AUTOSAR XML (schema 4-3-0)
package /Hackathon/Interfaces
  sender receiver interface WdgM_AliveInterface
    data AliveCounter: type=uint8
  client server interface WdgM_TriggerInterface
    operation Trigger: possible-error=E_NOT_OK
      arg SupervisionEntityId: direction=IN, type=uint16
    error E_NOT_OK: error-code=1
package /Hackathon/Components
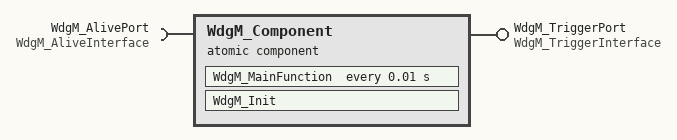
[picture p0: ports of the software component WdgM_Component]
  atomic sw component type WdgM_Component
    provide port WdgM_TriggerPort: provided-interface=WdgM_TriggerInterface
    require port WdgM_AlivePort: required-interface=WdgM_AliveInterface
    behavior WdgM_InternalBehavior
      runnable WdgM_MainFunction
      runnable WdgM_Init
      timing event WdgM_MainFunction_10ms: start-on-event=WdgM_MainFunction, period=0.01
      init event WdgM_Init_Event: start-on-event=WdgM_Init
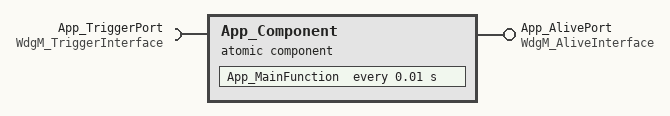
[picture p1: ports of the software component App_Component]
  atomic sw component type App_Component
    require port App_TriggerPort: required-interface=WdgM_TriggerInterface
    provide port App_AlivePort: provided-interface=WdgM_AliveInterface
    behavior App_InternalBehavior
      runnable App_MainFunction
      timing event App_MainFunction_10ms: start-on-event=App_MainFunction, period=0.01
  composition sw component type WdgM_App_Composition
    component WdgM_Instance: type=WdgM_Component
    component App_Instance: type=App_Component
    connect App_Instance.App_AlivePort -> WdgM_Instance.WdgM_AlivePort
    connect WdgM_Instance.WdgM_TriggerPort -> App_Instance.App_TriggerPort
